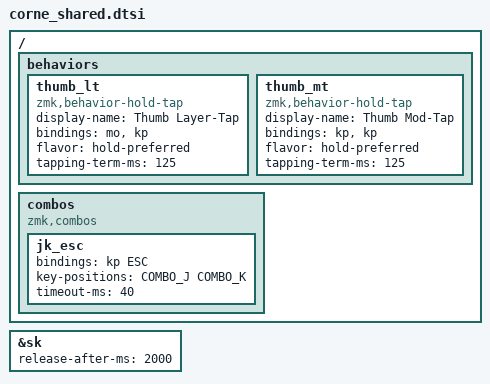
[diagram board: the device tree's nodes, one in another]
/*
 * Shared Corne layout: the 42 keys every Corne has.
 * This branch matches markstos' stock Corne layout:
 *   https://mark.stosberg.com/markstos-corne-3x5-1-keyboard-layout/
 *   https://github.com/markstos/qmk_userspace/blob/main/keyboards/crkbd/keymaps/markstos/keymap.c
 *
 * Edit keys HERE and both keyboards get the change.
 *   - config/corne.keymap         -> classic 42-key Corne (nice!nano)
 *   - config/eyelash_corne.keymap -> Eyelash Corne (adds joystick + knob keys)
 *
 * Each layer is split into rows so a keyboard with extra keys can slot them
 * in between the halves:
 *   <NAME>_L0 / _R0   top row       (left 6 / right 6)
 *   <NAME>_L1 / _R1   home row
 *   <NAME>_L2 / _R2   bottom row
 *   <NAME>_LT / _RT   thumbs        (left 3 / right 3)
 * Macro names keep the generic NUMBER/SYMBOL/CTRL names; in markstos terms
 * they are LOWER / RAISE / FUNC.
 *
 * Before including this file, a keymap must define the key positions
 * COMBO_J, COMBO_K (they differ per board).
 *
 * Changes from markstos stock:
 *   ZMK / wireless:
 *   - Bluetooth profile select + clear on FUNC (QMK version is wired, no BT).
 *   - QK_BOOT -> &bootloader.
 *   Windows + Mac instead of Linux (Mac uses Control <-> Command swap in
 *   System Settings > Keyboard > Modifier Keys, so Ctrl shortcuts work on both):
 *   - RAISE C/V: Linux COPY/PASTE codes -> Ctrl+C / Ctrl+V.
 *   - FUNC X/C/V: Shift+Del / Ctrl+Ins / Shift+Ins -> off / Windows area
 *     screenshot / Mac area screenshot (both copy to clipboard).
 *   - D+F dash combo removed (it broke `df` in nvim). Dash is RAISE + D.
 */

/* Screenshots: select an area with the mouse, copied to the clipboard */
#define WIN_SHOT_CLIP &kp LG(LS(S))       // Win+Shift+S
#define MAC_SHOT_CLIP &kp LC(LG(LS(N4)))  // Cmd+Ctrl+Shift+4 (same with the swap on)

#include <behaviors.dtsi>
#include <dt-bindings/zmk/bt.h>
#include <dt-bindings/zmk/keys.h>

#define L_QWERTY 0
#define L_NUMBER 1   /* markstos LOWER */
#define L_SYMBOL 2   /* markstos RAISE */
#define L_CTRL   3   /* markstos FUNC  */

/* ---------------------------------------------------------------- QWERTY */
#define QWERTY_L0 &kp TAB    &kp Q  &kp W  &kp E  &kp R  &kp T
#define QWERTY_R0 &kp Y      &kp U  &kp I  &kp O  &kp P  &kp DEL
#define QWERTY_L1 &sk LALT   &kp A  &kp S  &kp D  &kp F  &kp G
#define QWERTY_R1 &kp H      &kp J  &kp K  &kp L  &kp SQT  &sk RALT
#define QWERTY_L2 &sk LSHFT  &kp Z  &kp X  &kp C  &kp V  &kp B
#define QWERTY_R2 &kp N      &kp M  &kp COMMA  &kp DOT  &kp FSLH  &sl L_CTRL
#define QWERTY_LT                    &sk LCTRL  &thumb_mt LGUI ENTER  &thumb_lt L_NUMBER TAB
#define QWERTY_RT &thumb_lt L_SYMBOL BSPC  &kp SPACE  &sk LSHFT

/* ------------------------------------------------------- NUMBER (LOWER) */
#define NUMBER_L0 &trans  &kp EXCL  &kp AT     &kp HASH   &kp DLLR  &kp PRCNT
#define NUMBER_R0 &kp CARET  &kp AMPS  &kp STAR  &kp LPAR  &kp RPAR  &trans
#define NUMBER_L1 &trans  &kp N1    &kp N2     &kp N3     &kp N4    &kp N5
#define NUMBER_R1 &kp N6  &kp N7    &kp N8     &kp N9     &kp N0    &trans
#define NUMBER_L2 &trans  &none     &kp TILDE  &kp GRAVE  &kp LBKT  &kp LBRC
#define NUMBER_R2 &kp RBRC  &kp RBKT  &kp COMMA  &kp DOT  &kp FSLH  &trans
#define NUMBER_LT                   &trans  &trans  &trans
#define NUMBER_RT &trans  &trans  &kp COLON

/* ------------------------------------------------------- SYMBOL (RAISE) */
#define SYMBOL_L0 &trans  &kp DEL   &kp INS  &kp UNDER  &kp PLUS     &kp PG_UP
#define SYMBOL_R0 &none   &none     &none    &kp BSLH   &kp PIPE     &trans
#define SYMBOL_L1 &trans  &kp HOME  &kp END  &kp MINUS  &kp EQUAL    &kp PG_DN
#define SYMBOL_R1 &kp LEFT  &kp DOWN  &kp UP  &kp RIGHT  &kp K_APP  &trans
#define SYMBOL_L2 &trans  &kp LT    &kp GT   &kp LC(C)  &kp LC(V)    &kp SEMI
#define SYMBOL_R2 &kp C_PP  &kp C_PREV  &kp C_NEXT  &kp C_VOL_DN  &kp C_VOL_UP  &trans
#define SYMBOL_LT                   &thumb_mt LCTRL ESC  &trans  &none
#define SYMBOL_RT &trans  &trans  &trans

/* --------------------------------------------------------- CTRL (FUNC) */
#define CTRL_L0 &trans  &kp F1    &kp F2      &kp F3       &kp F4       &kp F5
#define CTRL_R0 &kp F6  &kp F7    &kp F8      &kp F9       &kp F10      &trans
#define CTRL_L1 &trans  &kp F11   &kp F12     &none        &none        &none
#define CTRL_R1 &bt BT_SEL 0  &bt BT_SEL 1  &bt BT_SEL 2  &bt BT_SEL 3  &bt BT_SEL 4  &trans
#define CTRL_L2 &trans  &kp CAPS  &none       WIN_SHOT_CLIP  MAC_SHOT_CLIP  &none
#define CTRL_R2 &bt BT_CLR  &none  &none  &none  &bootloader  &none
#define CTRL_LT                   &none  &none  &none
#define CTRL_RT &none  &none  &none

/* One-shot modifiers time out after 2 s (markstos ONESHOT_TIMEOUT). */
&sk {
    release-after-ms = <2000>;
};

/ {
    behaviors {
        /* Thumb layer-tap: hold-preferred, 125 ms (markstos TAPPING_TERM_THUMB). */
        thumb_lt: thumb_lt {
            compatible = "zmk,behavior-hold-tap";
            display-name = "Thumb Layer-Tap";
            #binding-cells = <2>;
            bindings = <&mo>, <&kp>;
            flavor = "hold-preferred";
            tapping-term-ms = <125>;
        };

        /* Thumb mod-tap: same timing. */
        thumb_mt: thumb_mt {
            compatible = "zmk,behavior-hold-tap";
            display-name = "Thumb Mod-Tap";
            #binding-cells = <2>;
            bindings = <&kp>, <&kp>;
            flavor = "hold-preferred";
            tapping-term-ms = <125>;
        };
    };

    combos {
        compatible = "zmk,combos";

        /* J+K = Escape, for Vim */
        jk_esc {
            bindings = <&kp ESC>;
            key-positions = <COMBO_J COMBO_K>;
            timeout-ms = <40>;
        };
    };
};
